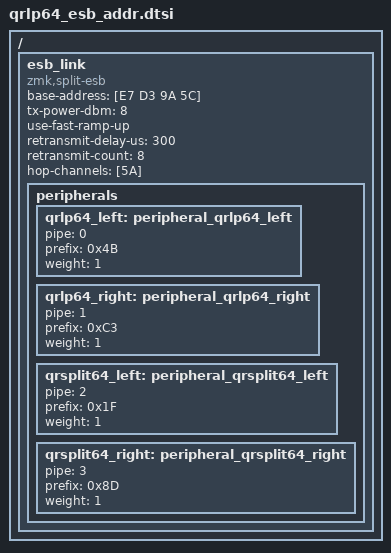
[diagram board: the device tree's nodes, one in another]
/ {
    esb_link {
        compatible = "zmk,split-esb";
        base-address = [E7 D3 9A 5C];
        tx-power-dbm = <8>;
        use-fast-ramp-up;
        retransmit-delay-us = <300>;
        retransmit-count = <8>;
        hop-channels = [5A];
        peripherals {
            qrlp64_left: peripheral_qrlp64_left {
                pipe = <0>;
                prefix = <0x4B>;
                weight = <1>;
            };
            qrlp64_right: peripheral_qrlp64_right {
                pipe = <1>;
                prefix = <0xC3>;
                weight = <1>;
            };
            qrsplit64_left: peripheral_qrsplit64_left {
                pipe = <2>;
                prefix = <0x1F>;
                weight = <1>;
            };
            qrsplit64_right: peripheral_qrsplit64_right {
                pipe = <3>;
                prefix = <0x8D>;
                weight = <1>;
            };
        };
    };
};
